# SYSCTL_1.0 register map
Vendor: Texas Instruments
Peripheral module from a debugger description file (folder mspm0l11xx_l13xx).
Registers are 32-bit, read-write, no defined reset value unless marked. A register's access mark holds for its fields unless they carry their own. Offsets are as the file gives them; lines under a group give offsets from that group; [hi:lo] are bit positions; {n}, {i} and the like mark numbered series; 'fields as' and 'values as' point back to an identical list; <NAME> marks a mode.

## SYSCTL
0x1020 SYSCTL_IIDX ro — SYSCTL interrupt index
  [1:0] STAT — The SYSCTL interrupt index (IIDX) register generates a value corresponding to the highest priority pending interrupt source. This value may be used as an address offset for fast, deterministic handling in the interrupt service routine. A read of the IIDX register will clear the corresponding interrupt status in the RIS and MIS registers.
    0=NO_INTR (No interrupt pending); 1=LFOSCGOOD (LFOSCGOOD interrupt pending); 2=ANACLKERR
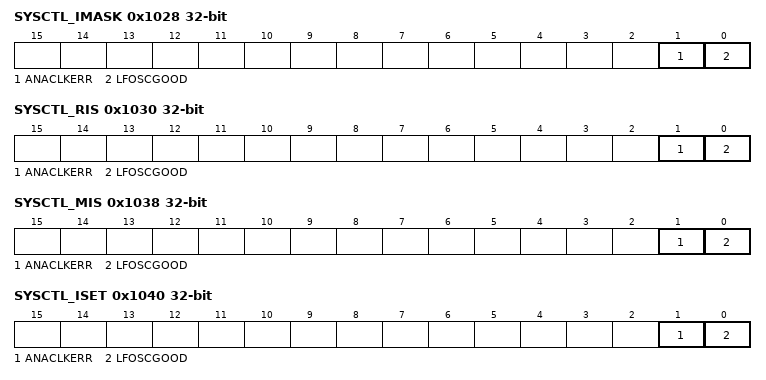
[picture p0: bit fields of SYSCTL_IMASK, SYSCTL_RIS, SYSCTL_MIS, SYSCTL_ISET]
0x1028 SYSCTL_IMASK — SYSCTL interrupt mask
  [1] ANACLKERR — Analog Clocking Consistency Error
    0=DISABLE; 1=ENABLE
  [0] LFOSCGOOD — Enable or disable the LFOSCGOOD interrupt. LFOSCGOOD indicates that the LFOSC has started successfully.
    0=DISABLE (Interrupt disabled); 1=ENABLE (Interrupt enabled)
0x1030 SYSCTL_RIS ro — SYSCTL raw interrupt status
  [1] ANACLKERR — Analog Clocking Consistency Error
    0=FALSE; 1=TRUE
  [0] LFOSCGOOD — Raw status of the LFOSCGOOD interrupt.
    0=FALSE (No interrupt pending); 1=TRUE (Interrupt pending)
0x1038 SYSCTL_MIS ro — SYSCTL masked interrupt status
  [1] ANACLKERR — Analog Clocking Consistency Error
    0=FALSE; 1=TRUE
  [0] LFOSCGOOD — Masked status of the LFOSCGOOD interrupt.
    0=FALSE (No interrupt pending); 1=TRUE (Interrupt pending)
0x1040 SYSCTL_ISET — SYSCTL interrupt set
  [1] ANACLKERR — Analog Clocking Consistency Error
    0=NO_EFFECT; 1=SET
  [0] LFOSCGOOD — Set the LFOSCGOOD interrupt.
    0=NO_EFFECT (Writing 0h hs no effect); 1=SET (Set interrupt)
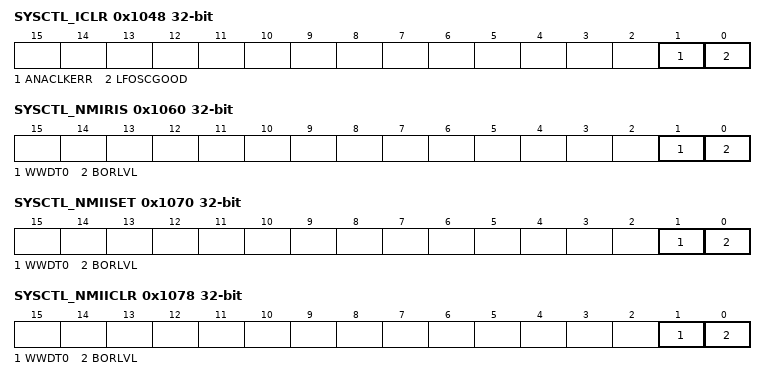
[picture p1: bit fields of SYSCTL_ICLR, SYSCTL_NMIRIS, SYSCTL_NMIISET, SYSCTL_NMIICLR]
0x1048 SYSCTL_ICLR — SYSCTL interrupt clear
  [1] ANACLKERR — Analog Clocking Consistency Error
    0=NO_EFFECT; 1=CLR
  [0] LFOSCGOOD — Clear the LFOSCGOOD interrupt.
    0=NO_EFFECT (Writing 0h has no effect); 1=CLR (Clear interrupt)
0x1050 SYSCTL_NMIIIDX ro — NMI interrupt index
  [1:0] STAT — The NMI interrupt index (NMIIIDX) register generates a value corresponding to the highest priority pending NMI source. This value may be used as an address offset for fast, deterministic handling in the NMI service routine. A read of the NMIIIDX register will clear the corresponding interrupt status in the NMIRIS register.
    0=NO_INTR (No NMI pending); 1=BORLVL (BOR Threshold NMI pending); 2=WWDT0
0x1060 SYSCTL_NMIRIS ro — NMI raw interrupt status
  [1] WWDT0 — Watch Dog 0 Fault
    0=FALSE; 1=TRUE
  [0] BORLVL — Raw status of the BORLVL NMI
    0=FALSE (No interrupt pending); 1=TRUE (Interrupt pending)
0x1070 SYSCTL_NMIISET — NMI interrupt set
  [1] WWDT0 — Watch Dog 0 Fault
    0=NO_EFFECT; 1=SET
  [0] BORLVL — Set the BORLVL NMI
    0=NO_EFFECT (Writing 0h hs no effect); 1=SET (Set interrupt)
0x1078 SYSCTL_NMIICLR — NMI interrupt clear
  [1] WWDT0 — Watch Dog 0 Fault
    0=NO_EFFECT; 1=CLR
  [0] BORLVL — Clr the BORLVL NMI
    0=NO_EFFECT (Writing 0h hs no effect); 1=CLR (Clear interrupt)
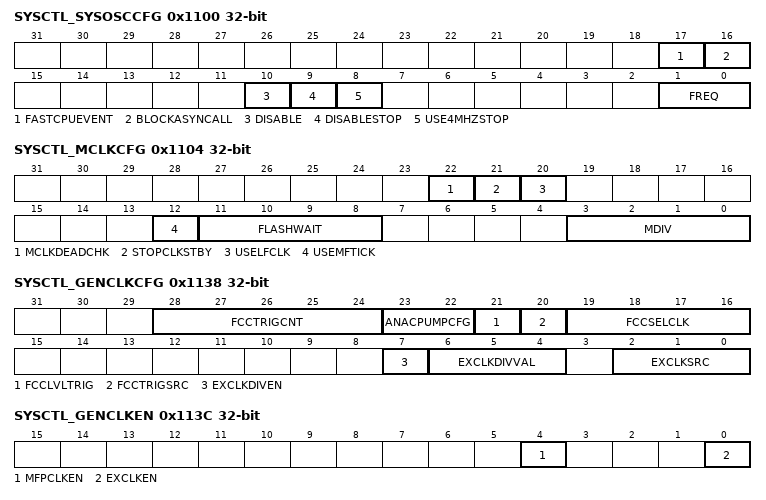
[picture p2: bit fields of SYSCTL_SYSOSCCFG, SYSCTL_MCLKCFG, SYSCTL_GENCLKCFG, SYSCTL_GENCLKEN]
0x1100 SYSCTL_SYSOSCCFG — SYSOSC configuration
  [17] FASTCPUEVENT — FASTCPUEVENT may be used to assert a fast clock request when an interrupt is asserted to the CPU, reducing interrupt latency.
    0=DISABLE (An interrupt to the CPU will not assert a fast clock request); 1=ENABLE (An interrupt to the CPU will assert a fast clock request)
  [16] BLOCKASYNCALL — BLOCKASYNCALL may be used to mask block all asynchronous fast clock requests, preventing hardware from dynamically changing the active clock configuration when operating in a given mode.
    0=DISABLE (Asynchronous fast clock requests are controlled by the requesting peripheral); 1=ENABLE (All asynchronous fast clock requests are blocked)
  [10] DISABLE — DISABLE sets the SYSOSC enable/disable policy. SYSOSC may be powered off in RUN, SLEEP, and STOP modes to reduce power consumption. When SYSOSC is disabled, MCLK and ULPCLK are sourced from LFCLK.
    0=DISABLE (Do not disable SYSOSC); 1=ENABLE (Disable SYSOSC immediately and source MCLK and ULPCLK from LFCLK)
  [9] DISABLESTOP — DISABLESTOP sets the SYSOSC stop mode enable/disable policy. When operating in STOP mode, the SYSOSC may be automatically disabled. When set, ULPCLK will run from LFCLK in STOP mode and SYSOSC will be disabled to reduce power consumption.
    0=DISABLE (Do not disable SYSOSC in STOP mode); 1=ENABLE (Disable SYSOSC in STOP mode and source ULPCLK from LFCLK)
  [8] USE4MHZSTOP — USE4MHZSTOP sets the SYSOSC stop mode frequency policy. When entering STOP mode, the SYSOSC frequency may be automatically switched to 4MHz to reduce SYSOSC power consumption.
    0=DISABLE (Do not gear shift the SYSOSC to 4MHz in STOP mode); 1=ENABLE (Gear shift SYSOSC to 4MHz in STOP mode)
  [1:0] FREQ — Target operating frequency for the system oscillator (SYSOSC)
    0=SYSOSCBASE (Base frequency (32MHz)); 1=SYSOSC4M (Low frequency (4MHz)); 2=SYSOSCUSER (User-trimmed frequency (16 or 24 MHz)); 3=SYSOSCTURBO (Turbo frequency (48MHz))
0x1104 SYSCTL_MCLKCFG — Main clock (MCLK) configuration
  [22] MCLKDEADCHK — MCLKDEADCHK enables or disables the continuous MCLK dead check monitor. LFCLK must be running before MCLKDEADCHK is enabled.
    0=DISABLE (The MCLK dead check monitor is disabled); 1=ENABLE (The MCLK dead check monitor is enabled)
  [21] STOPCLKSTBY — STOPCLKSTBY sets the STANDBY mode policy (STANDBY0 or STANDBY1). When set, ULPCLK and LFCLK are disabled to all peripherals in STANDBY mode, with the exception of TIMG0 and TIMG1 which continue to run. Wake-up is only possible via an asynchronous fast clock request.
    0=DISABLE (ULPCLK/LFCLK runs to all PD0 peripherals in STANDBY mode); 1=ENABLE (ULPCLK/LFCLK is disabled to all peripherals in STANDBY mode except TIMG0 and TIMG1)
  [20] USELFCLK — USELFCLK sets the MCLK source policy. Set USELFCLK to use LFCLK as the MCLK source. Note that setting USELFCLK does not disable SYSOSC, and SYSOSC remains available for direct use by analog modules.
    0=DISABLE (MCLK will not use the low frequency clock (LFCLK)); 1=ENABLE (MCLK will use the low frequency clock (LFCLK))
  [12] USEMFTICK — USEMFTICK specifies whether the 4MHz constant-rate clock (MFCLK) to peripherals is enabled or disabled. When enabled, MDIV must be disabled (set to 0h=/1).
    0=DISABLE (The 4MHz rate MFCLK to peripherals is enabled); 1=ENABLE (The 4MHz rate MFCLK to peripherals is enabled.)
  [11:8] FLASHWAIT — FLASHWAIT specifies the number of flash wait states when MCLK is sourced from HSCLK. FLASHWAIT has no effect when MCLK is sourced from SYSOSC or LFCLK.
    0=WAIT0 (No flash wait states are applied); 1=WAIT1 (One flash wait state is applied); 2=WAIT2 (2 flash wait states are applied)
  [3:0] MDIV — MDIV may be used to divide the MCLK frequency when MCLK is sourced from SYSOSC. MDIV=0h corresponds to /1 (no divider). MDIV=1h corresponds to /2 (divide-by-2). MDIV=Fh corresponds to /16 (divide-by-16). MDIV may be set between /1 and /16 on an integer basis.
0x1138 SYSCTL_GENCLKCFG — General clock configuration
  [28:24] FCCTRIGCNT — FCCTRIGCNT specifies the number of trigger clock periods in the trigger window. FCCTRIGCNT=0h (one trigger clock period) up to 1Fh (32 trigger clock periods) may be specified.
  [23:22] ANACPUMPCFG — ANACPUMPCFG selects the analog mux charge pump (VBOOST) enable method.
    0=ONDEMAND (VBOOST is enabled on request from a COMP, GPAMP, or OPA); 1=ONACTIVE (VBOOST is enabled when the device is in RUN or SLEEP mode, or when a COMP/GPAMP/OPA is enabled); 2=ONALWAYS (VBOOST is always enabled)
  [21] FCCLVLTRIG — FCCLVLTRIG selects the frequency clock counter (FCC) trigger mode.
    0=RISE2RISE (Rising edge to rising edge triggered); 1=LEVEL (Level triggered)
  [20] FCCTRIGSRC — FCCTRIGSRC selects the frequency clock counter (FCC) trigger source.
    0=EXTPIN (FCC trigger is the external pin); 1=LFCLK (FCC trigger is the LFCLK)
  [19:16] FCCSELCLK — FCCSELCLK selectes the frequency clock counter (FCC) clock source.
    0=MCLK (FCC clock is MCLK); 1=SYSOSC (FCC clock is SYSOSC); 3=EXTCLK (FCC clock is the CLK_OUT selection); 7=FCCIN (FCC clock is the FCCIN external input)
  [7] EXCLKDIVEN — EXCLKDIVEN enables or disables the divider function of the CLK_OUT external clock output block.
    0=PASSTHRU (CLock divider is disabled (passthrough, EXCLKDIVVAL is not applied)); 1=ENABLE (Clock divider is enabled (EXCLKDIVVAL is applied))
  [6:4] EXCLKDIVVAL — EXCLKDIVVAL selects the divider value for the divider in the CLK_OUT external clock output block.
    0=DIV2 (CLK_OUT source is divided by 2); 1=DIV4 (CLK_OUT source is divided by 4); 2=DIV6 (CLK_OUT source is divided by 6); 3=DIV8 (CLK_OUT source is divided by 8); 4=DIV10 (CLK_OUT source is divided by 10); 5=DIV12 (CLK_OUT source is divided by 12); 6=DIV14 (CLK_OUT source is divided by 14); 7=DIV16 (CLK_OUT source is divided by 16)
  [2:0] EXCLKSRC — EXCLKSRC selects the source for the CLK_OUT external clock output block. ULPCLK and MFPCLK require the CLK_OUT divider (EXCLKDIVEN) to be enabled
    0=SYSOSC (CLK_OUT is SYSOSC); 1=ULPCLK (CLK_OUT is ULPCLK (EXCLKDIVEN must be enabled)); 2=LFCLK (CLK_OUT is LFCLK); 3=MFPCLK (CLK_OUT is MFPCLK (EXCLKDIVEN must be enabled))
0x113C SYSCTL_GENCLKEN — General clock enable control
  [4] MFPCLKEN — MFPCLKEN enables the middle frequency precision clock (MFPCLK).
    0=DISABLE (MFPCLK is disabled); 1=ENABLE (MFPCLK is enabled)
  [0] EXCLKEN — EXCLKEN enables the CLK_OUT external clock output block.
    0=DISABLE (CLK_OUT block is disabled); 1=ENABLE (CLK_OUT block is enabled)
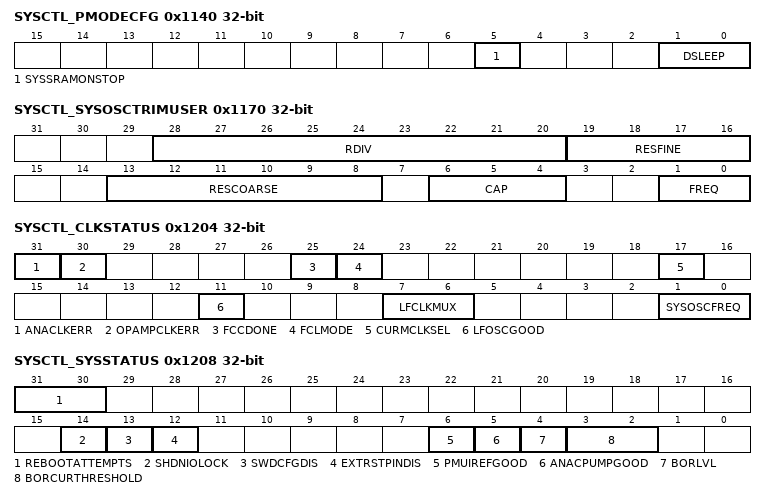
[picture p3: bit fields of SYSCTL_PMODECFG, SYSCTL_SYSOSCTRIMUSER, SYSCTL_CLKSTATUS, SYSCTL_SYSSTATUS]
0x1140 SYSCTL_PMODECFG — Power mode configuration
  [5] SYSSRAMONSTOP — SYSSRAMONSTOP selects whether the SRAM controller is enabled or disabled in STOP mode.
    0=DISABLE (SRAM controller is disabled in STOP mode (lower power consumption)); 1=ENABLE (SRAM controller is left enabled in STOP mode (faster wake-up))
  [1:0] DSLEEP — DSLEEP selects the operating mode to enter upon a DEEPSLEEP request from the CPU.
    0=STOP (STOP mode is entered); 1=STANDBY (STANDBY mode is entered); 2=SHUTDOWN (SHUTDOWN mode is entered)
0x1150 SYSCTL_FCC ro — Frequency clock counter (FCC) count
  [21:0] DATA — Frequency clock counter (FCC) count value.
0x1170 SYSCTL_SYSOSCTRIMUSER — SYSOSC user-specified trim
  [28:20] RDIV — RDIV specifies the frequency correction loop (FCL) resistor trim. This value changes with the target frequency.
  [19:16] RESFINE — RESFINE specifies the resister fine trim. This value changes with the target frequency.
  [13:8] RESCOARSE — RESCOARSE specifies the resister coarse trim. This value changes with the target frequency.
  [6:4] CAP — CAP specifies the SYSOSC capacitor trim. This value changes with the target frequency.
  [1:0] FREQ — FREQ specifies the target user-trimmed frequency for SYSOSC.
    1=SYSOSC16M (16MHz user frequency); 2=SYSOSC24M (24MHz user frequency)
0x1178 SYSCTL_SRAMBOUNDARY — SRAM Write Boundary
  [19:5] ADDR — SRAM boundary configuration. The value configured into this acts such that: SRAM accesses to addresses less than or equal value will be RW only. SRAM accesses to addresses greater than value will be RX only. Value of 0 is not valid (system will have no stack). If set to 0, the system acts as if the entire SRAM is RWX. Any non-zero value can be configured, including a value = SRAM size.
0x1180 SYSCTL_SYSTEMCFG — System configuration
  [0] WWDTLP0RSTDIS — WWDTLP0RSTDIS specifies whether a WWDT Error Event will trigger a BOOTRST or an NMI.
    0=FALSE (WWDTLP0 Error Event will trigger a BOOTRST); 1=TRUE (WWDTLP0 Error Event will trigger an NMI)
0x1200 SYSCTL_WRITELOCK — SYSCTL register write lockout
  [0] ACTIVE — ACTIVE controls whether critical SYSCTL registers are write protected or not.
    0=DISABLE (Allow writes to lockable registers); 1=ENABLE (Disallow writes to lockable registers)
0x1204 SYSCTL_CLKSTATUS ro — Clock module (CKM) status
  [31] ANACLKERR — ANACLKERR is set when the device clock configuration does not support an enabled analog peripheral mode and the analog peripheral may not be functioning as expected.
    0=FALSE (No analog clock errors detected); 1=TRUE (Analog clock error detected)
  [30] OPAMPCLKERR — OPAMPCLKERR is set when the device clock configuration does not support an enabled OPA mode and the OPA may not be functioning as expected.
    0=FALSE (No OPA clock generation errors detected); 1=TRUE (OPA clock generation error detected)
  [25] FCCDONE — FCCDONE indicates when a frequency clock counter capture is complete.
    0=NOTDONE (FCC capture is not done); 1=DONE (FCC capture is done)
  [24] FCLMODE — FCLMODE indicates if the SYSOSC frequency correction loop (FCL) is enabled.
    0=DISABLED (SYSOSC FCL is disabled); 1=ENABLED (SYSOSC FCL is enabled)
  [17] CURMCLKSEL — CURMCLKSEL indicates if MCLK is currently sourced from LFCLK.
    0=NOTLFCLK (MCLK is not sourced from LFCLK); 1=LFCLK (MCLK is sourced from LFCLK)
  [11] LFOSCGOOD — LFOSCGOOD indicates when the LFOSC startup has completed and the LFOSC is ready for use.
    0=FALSE (LFOSC is not ready); 1=TRUE (LFOSC is ready)
  [7:6] LFCLKMUX — LFCLKMUX indicates if LFCLK is sourced from the internal LFOSC, the low frequency crystal (LFXT), or the LFCLK_IN digital clock input.
    0=LFOSC (LFCLK is sourced from the internal LFOSC); 1=LFXT (LFCLK is sourced from the LFXT (crystal)); 2=EXLF (LFCLK is sourced from LFCLK_IN (external digital clock input))
  [1:0] SYSOSCFREQ — SYSOSCFREQ indicates the current SYSOSC operating frequency.
    0=SYSOSC32M (SYSOSC is at base frequency (32MHz)); 1=SYSOSC4M (SYSOSC is at low frequency (4MHz)); 2=SYSOSCUSER (SYSOSC is at the user-trimmed frequency (16 or 24MHz)); 3=SYSOSCTURBO (Reserved)
0x1208 SYSCTL_SYSSTATUS ro — System status information
  [31:30] REBOOTATTEMPTS — REBOOTATTEMPTS indicates the number of boot attempts taken before the user application starts.
  [14] SHDNIOLOCK — SHDNIOLOCK indicates when IO is locked due to SHUTDOWN
    0=FALSE (IO IS NOT Locked due to SHUTDOWN); 1=TRUE (IO IS Locked due to SHUTDOWN)
  [13] SWDCFGDIS — SWDCFGDIS indicates when user has disabled the use of SWD Port
    0=FALSE (SWD Port Enabled); 1=TRUE (SWD Port Disabled)
  [12] EXTRSTPINDIS — EXTRSTPINDIS indicates when user has disabled the use of external reset pin
    0=FALSE (External Reset Pin Enabled); 1=TRUE (External Reset Pin Disabled)
  [6] PMUIREFGOOD — PMUIREFGOOD is set by hardware when the PMU current reference is ready.
    0=FALSE (IREF is not ready); 1=TRUE (IREF is ready)
  [5] ANACPUMPGOOD — ANACPUMPGOOD is set by hardware when the VBOOST analog mux charge pump is ready.
    0=FALSE (VBOOST is not ready); 1=TRUE (VBOOST is ready)
  [4] BORLVL — BORLVL indicates if a BOR event occured and the BOR threshold was switched to BOR0 by hardware.
    0=FALSE (No BOR violation occured); 1=TRUE (A BOR violation occured and the BOR threshold was switched to BOR0)
  [3:2] BORCURTHRESHOLD — BORCURTHRESHOLD indicates the active brown-out reset supply monitor configuration.
    0=BORMIN (Default minimum threshold; a BOR0- violation triggers a BOR); 1=BORLEVEL1 (A BOR1- violation generates a BORLVL interrupt); 2=BORLEVEL2 (A BOR2- violation generates a BORLVL interrupt); 3=BORLEVEL3 (A BOR3- violation generates a BORLVL interrupt)
0x1220 SYSCTL_RSTCAUSE ro — Reset cause
  [4:0] ID — ID is a read-to-clear field which indicates the lowest level reset cause since the last read.
    0=NORST (No reset since last read); 1=PORHWFAIL (POR- violation, SHUTDNSTOREx or PMU trim parity fault); 2=POREXNRST (NRST triggered POR (>1s hold)); 3=PORSW (Software triggered POR); 4=BORSUPPLY (BOR0- violation); 5=BORWAKESHUTDN (SHUTDOWN mode exit); 8=BOOTNONPMUPARITY (Non-PMU trim parity fault); 9=BOOTCLKFAIL (Fatal clock failure); 10=BOOTSW (Software triggered BOOTRST); 12=BOOTEXNRST (NRST triggered BOOTRST (<1s hold)); 16=SYSBSLEXIT (BSL exit); 17=SYSBSLENTRY (BSL entry); 18=SYSWWDT0 (WWDT0 violation); 19=SYSWWDT1 (WWDT1 violation); 20=SYSFLASHECC (Flash uncorrectable ECC error); 21=SYSCPULOCK (CPULOCK violation); 26=SYSDBG (Debug triggered SYSRST); 27=SYSSW (Software triggered SYSRST); 28=CPUDBG (Debug triggered CPURST); 29=CPUSW (Software triggered CPURST)
0x1300 SYSCTL_RESETLEVEL — Reset level for application-triggered reset command
  [2:0] LEVEL — LEVEL is used to specify the type of reset to be issued when RESETCMD is set to generate a software triggered reset.
    0=CPU (Issue a SYSRST (CPU plus peripherals only)); 1=BOOT (Issue a BOOTRST (CPU, peripherals, and boot configuration routine)); 2=BOOTLOADERENTRY (Issue a SYSRST and enter the boot strap loader (BSL)); 3=POR (Issue a power-on reset (POR)); 4=BOOTLOADEREXIT (Issue a SYSRST and exit the boot strap loader (BSL))
0x1304 SYSCTL_RESETCMD — Execute an application-triggered reset command
  [0] GO — Execute the reset specified in RESETLEVEL.LEVEL. Must be written together with the KEY.
    1=TRUE (Issue reset)
0x1308 SYSCTL_BORTHRESHOLD — BOR threshold selection
  [1:0] LEVEL — LEVEL specifies the desired BOR threshold and BOR mode.
    values as SYSCTL_SYSSTATUS.BORCURTHRESHOLD
0x130C SYSCTL_BORCLRCMD — Set the BOR threshold
  [0] GO — GO clears any prior BOR violation status indications and attempts to change the active BOR mode to that specified in the LEVEL field of the BORTHRESHOLD register.
    1=TRUE (Issue clear)
0x1310 SYSCTL_SYSOSCFCLCTL — SYSOSC frequency correction loop (FCL) ROSC enable
  [0] SETUSEFCL — Set SETUSEFCL to enable the frequency correction loop in SYSOSC. An appropriate resistor must be populated on the ROSC pin. Once enabled, this state is locked until the next BOOTRST.
    1=TRUE (Enable the SYSOSC FCL)
0x131C SYSCTL_SHDNIOREL — SHUTDOWN IO release control
  [0] RELEASE — Set RELEASE to release the IO after a SHUTDOWN mode exit.
    1=TRUE (Release IO)
0x1320 SYSCTL_EXRSTPIN — Disable the reset function of the NRST pin
  [0] DISABLE — Set DISABLE to disable the reset function of the NRST pin. Once set, this configuration is locked until the next POR.
    0=FALSE (Reset function of NRST pin is enabled); 1=TRUE (Reset function of NRST pin is disabled)
0x1324 SYSCTL_SYSSTATUSCLR — Clear sticky bits of SYSSTATUS
  [0] ALLECC — Set ALLECC to clear all ECC related SYSSTATUS indicators.
    1=CLEAR (Clear ECC error state)
0x1328 SYSCTL_SWDCFG — Disable the SWD function on the SWD pins
  [0] DISABLE — Set DISABLE to disable the SWD function on SWD pins, allowing the SWD pins to be used as GPIO.
    1=TRUE (Disable SWD function on SWD pins)
0x132C SYSCTL_FCCCMD — Frequency clock counter start capture
  [0] GO — Set GO to start a capture with the frequency clock counter (FCC).
    1=TRUE
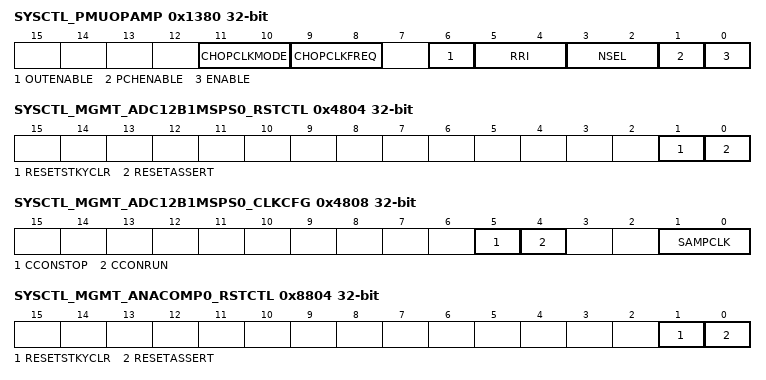
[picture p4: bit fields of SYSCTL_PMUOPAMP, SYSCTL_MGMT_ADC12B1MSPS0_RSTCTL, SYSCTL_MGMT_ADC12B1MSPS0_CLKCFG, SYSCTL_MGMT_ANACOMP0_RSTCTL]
0x1380 SYSCTL_PMUOPAMP — GPAMP control
  [11:10] CHOPCLKMODE — CHOPCLKMODE selects the GPAMP chopping mode.
    0=CHOPDISABLED (Chopping disabled); 1=REGCHOP (Normal chopping); 2=ADCASSIST (ADC Assisted chopping)
  [9:8] CHOPCLKFREQ — CHOPCLKFREQ selects the GPAMP chopping clock frequency
    0=CLK16KHZ (16kHz); 1=CLK8KHZ (8kHz); 2=CLK4KHZ (4kHz); 3=CLK2KHZ (2kHz)
  [6] OUTENABLE — Set OUTENABLE to connect the GPAMP output signal to the GPAMP_OUT pin
    0=FALSE (GPAMP_OUT signal is not connected to the GPAMP_OUT pin); 1=TRUE (GPAMP_OUT signal is connected to the GPAMP_OUT pin)
  [5:4] RRI — RRI selects the rail-to-rail input mode.
    0=MODE0 (PMOS input pairs); 1=MODE1 (NMOS input pairs); 2=MODE2 (Rail-to-rail mode); 3=MODE3 (Sample channel 0)
  [3:2] NSEL — NSEL selects the GPAMP negative channel input.
    0=SEL0 (GPAMP_OUT pin connected to negative channel); 1=SEL1 (GPAMP_IN- pin connected to negative channel); 2=SEL2 (GPAMP_OUT signal connected to negative channel); 3=SEL3 (No channel selected)
  [1] PCHENABLE — Set PCHENABLE to enable the positive channel input.
    0=FALSE (Positive channel disabled); 1=TRUE (GPAMP_IN+ connected to positive channel)
  [0] ENABLE — Set ENABLE to turn on the GPAMP.
    0=FALSE (GPAMP is disabled); 1=TRUE (GPAMP is enabled)
{0x1400+4i} SYSCTL_SHUTDNSTORE{i} (i=0..3) — Shutdown storage memory (byte {i})
  [7:0] DATA — Shutdown storage byte {i}
0x4800 SYSCTL_MGMT_ADC12B1MSPS0_PWREN — IP Enable Register
  [0] ENABLE — IP Enable
    0=Disable; 1=Enable
0x4804 SYSCTL_MGMT_ADC12B1MSPS0_RSTCTL — Power Control Register - Write Only Register, Always Read as 0
  [1] RESETSTKYCLR — Clear the RESET STICKY Bit
    1=Clear
  [0] RESETASSERT — Assert Reset to IP Domain.
    1=Do
0x4808 SYSCTL_MGMT_ADC12B1MSPS0_CLKCFG — IP Clock Configuration Register
  [5] CCONSTOP — Conversion Clock is ON during STOP Mode
    0=Disable; 1=Enable
  [4] CCONRUN — Conversion Clock is ON during RUN Mode
    0=Disable; 1=Enable
  [1:0] SAMPCLK — Sample Window Clock
    0=ULPCLK; 1=SYSOSC; 2=HFCLK
0x4814 SYSCTL_MGMT_ADC12B1MSPS0_STAT ro — IP State Register - Read Only
  [16] RESETSTKY — IP has been Reset
    0=clear; 1=Set
0x8800 SYSCTL_MGMT_ANACOMP0_PWREN — IP Enable Register
  [0] ENABLE — IP Enable
    0=Disable; 1=Enable
0x8804 SYSCTL_MGMT_ANACOMP0_RSTCTL — Power Control Register - Write Only Register, Always Read as 0
  fields as SYSCTL_MGMT_ADC12B1MSPS0_RSTCTL
0x8808 SYSCTL_MGMT_ANACOMP0_CLKCFG — IP Clock Configuration Register
  [8] BLOCKASYNC — Async Clock Request is blocked from starting SYSOSC or forcing bus clock to 32MHz
    0=Disable; 1=Enable
0x8814 SYSCTL_MGMT_ANACOMP0_STAT ro — IP State Register - Read Only
  [16] RESETSTKY — IP has been Reset
    0=clear; 1=Set
0x20800 SYSCTL_MGMT_OPAMP0_PWREN — IP Enable Register
  [0] ENABLE — IP Enable
    0=Disable; 1=Enable
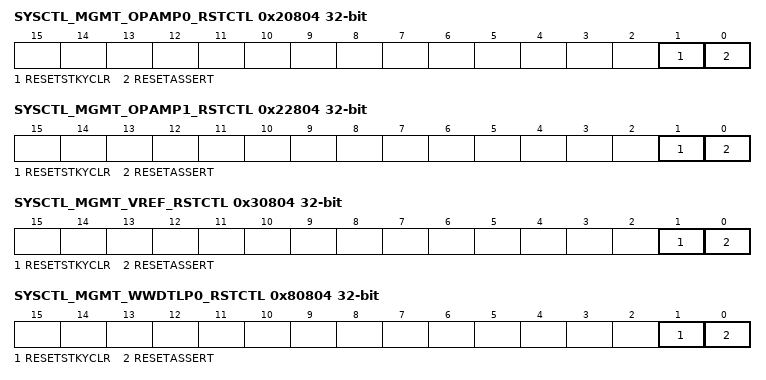
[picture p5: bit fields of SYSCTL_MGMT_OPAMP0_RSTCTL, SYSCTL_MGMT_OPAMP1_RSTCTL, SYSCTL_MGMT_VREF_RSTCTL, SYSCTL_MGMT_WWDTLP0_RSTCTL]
0x20804 SYSCTL_MGMT_OPAMP0_RSTCTL — Power Control Register - Write Only Register, Always Read as 0
  fields as SYSCTL_MGMT_ADC12B1MSPS0_RSTCTL
0x20814 SYSCTL_MGMT_OPAMP0_STAT ro — IP State Register - Read Only
  [16] RESETSTKY — IP has been Reset
    0=clear; 1=Set
0x22800 SYSCTL_MGMT_OPAMP1_PWREN — IP Enable Register
  [0] ENABLE — IP Enable
    0=Disable; 1=Enable
0x22804 SYSCTL_MGMT_OPAMP1_RSTCTL — Power Control Register - Write Only Register, Always Read as 0
  fields as SYSCTL_MGMT_ADC12B1MSPS0_RSTCTL
0x22814 SYSCTL_MGMT_OPAMP1_STAT ro — IP State Register - Read Only
  [16] RESETSTKY — IP has been Reset
    0=clear; 1=Set
0x30800 SYSCTL_MGMT_VREF_PWREN — IP Enable Register
  [0] ENABLE — IP Enable
    0=Disable; 1=Enable
0x30804 SYSCTL_MGMT_VREF_RSTCTL — Power Control Register - Write Only Register, Always Read as 0
  fields as SYSCTL_MGMT_ADC12B1MSPS0_RSTCTL
0x30814 SYSCTL_MGMT_VREF_STAT ro — IP State Register - Read Only
  [16] RESETSTKY — IP has been Reset
    0=clear; 1=Set
0x80800 SYSCTL_MGMT_WWDTLP0_PWREN — IP Enable Register
  [0] ENABLE — IP Enable
    0=Disable; 1=Enable
0x80804 SYSCTL_MGMT_WWDTLP0_RSTCTL — Power Control Register - Write Only Register, Always Read as 0
  fields as SYSCTL_MGMT_ADC12B1MSPS0_RSTCTL
0x80814 SYSCTL_MGMT_WWDTLP0_STAT ro — IP State Register - Read Only
  [16] RESETSTKY — IP has been Reset
    0=clear; 1=Set
{0x84800+0x2000*i} SYSCTL_MGMT_GPTIMER16B2CCLP{i}_PWREN (i=0..2) — IP Enable Register
  [0] ENABLE — IP Enable
    0=Disable; 1=Enable
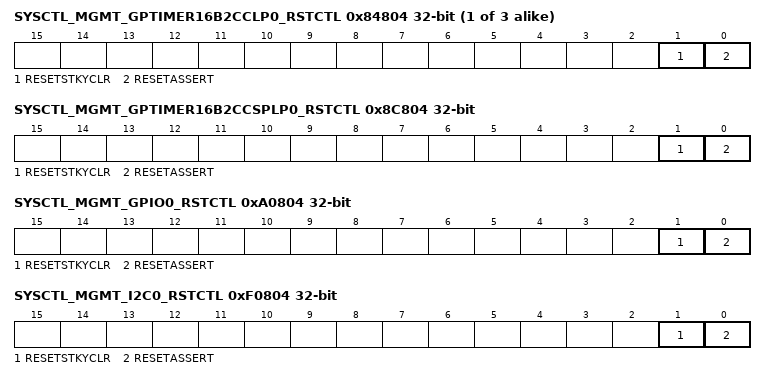
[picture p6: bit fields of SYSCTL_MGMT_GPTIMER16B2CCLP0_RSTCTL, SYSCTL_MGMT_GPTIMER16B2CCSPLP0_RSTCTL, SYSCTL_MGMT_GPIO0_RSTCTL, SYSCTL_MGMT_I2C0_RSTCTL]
{0x84804+0x2000*i} SYSCTL_MGMT_GPTIMER16B2CCLP{i}_RSTCTL (i=0..2) — Power Control Register - Write Only Register, Always Read as 0
  fields as SYSCTL_MGMT_ADC12B1MSPS0_RSTCTL
{0x84814+0x2000*i} SYSCTL_MGMT_GPTIMER16B2CCLP{i}_STAT ro (i=0..2) — IP State Register - Read Only
  [16] RESETSTKY — IP has been Reset
    0=clear; 1=Set
0x8C800 SYSCTL_MGMT_GPTIMER16B2CCSPLP0_PWREN — IP Enable Register
  [0] ENABLE — IP Enable
    0=Disable; 1=Enable
0x8C804 SYSCTL_MGMT_GPTIMER16B2CCSPLP0_RSTCTL — Power Control Register - Write Only Register, Always Read as 0
  fields as SYSCTL_MGMT_ADC12B1MSPS0_RSTCTL
0x8C814 SYSCTL_MGMT_GPTIMER16B2CCSPLP0_STAT ro — IP State Register - Read Only
  [16] RESETSTKY — IP has been Reset
    0=clear; 1=Set
0xA0800 SYSCTL_MGMT_GPIO0_PWREN — IP Enable Register
  [0] ENABLE — IP Enable
    0=Disable; 1=Enable
0xA0804 SYSCTL_MGMT_GPIO0_RSTCTL — Power Control Register - Write Only Register, Always Read as 0
  fields as SYSCTL_MGMT_ADC12B1MSPS0_RSTCTL
0xA0814 SYSCTL_MGMT_GPIO0_STAT ro — IP State Register - Read Only
  [16] RESETSTKY — IP has been Reset
    0=clear; 1=Set
0xF0800 SYSCTL_MGMT_I2C0_PWREN — IP Enable Register
  [0] ENABLE — IP Enable
    0=Disable; 1=Enable
0xF0804 SYSCTL_MGMT_I2C0_RSTCTL — Power Control Register - Write Only Register, Always Read as 0
  fields as SYSCTL_MGMT_ADC12B1MSPS0_RSTCTL
0xF0808 SYSCTL_MGMT_I2C0_CLKCFG — IP Clock Configuration Register
  fields as SYSCTL_MGMT_ANACOMP0_CLKCFG
0xF0814 SYSCTL_MGMT_I2C0_STAT ro — IP State Register - Read Only
  [16] RESETSTKY — IP has been Reset
    0=clear; 1=Set
0xF2800 SYSCTL_MGMT_I2C1_PWREN — IP Enable Register
  [0] ENABLE — IP Enable
    0=Disable; 1=Enable
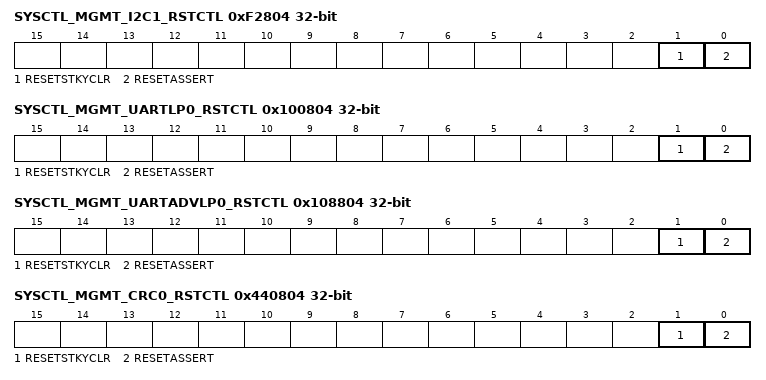
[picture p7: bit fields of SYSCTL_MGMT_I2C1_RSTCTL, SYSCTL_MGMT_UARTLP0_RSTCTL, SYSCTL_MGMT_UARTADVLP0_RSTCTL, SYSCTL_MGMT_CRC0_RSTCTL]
0xF2804 SYSCTL_MGMT_I2C1_RSTCTL — Power Control Register - Write Only Register, Always Read as 0
  fields as SYSCTL_MGMT_ADC12B1MSPS0_RSTCTL
0xF2808 SYSCTL_MGMT_I2C1_CLKCFG — IP Clock Configuration Register
  fields as SYSCTL_MGMT_ANACOMP0_CLKCFG
0xF2814 SYSCTL_MGMT_I2C1_STAT ro — IP State Register - Read Only
  [16] RESETSTKY — IP has been Reset
    0=clear; 1=Set
0x100800 SYSCTL_MGMT_UARTLP0_PWREN — IP Enable Register
  [0] ENABLE — IP Enable
    0=Disable; 1=Enable
0x100804 SYSCTL_MGMT_UARTLP0_RSTCTL — Power Control Register - Write Only Register, Always Read as 0
  fields as SYSCTL_MGMT_ADC12B1MSPS0_RSTCTL
0x100808 SYSCTL_MGMT_UARTLP0_CLKCFG — IP Clock Configuration Register
  fields as SYSCTL_MGMT_ANACOMP0_CLKCFG
0x100814 SYSCTL_MGMT_UARTLP0_STAT ro — IP State Register - Read Only
  [16] RESETSTKY — IP has been Reset
    0=clear; 1=Set
0x108800 SYSCTL_MGMT_UARTADVLP0_PWREN — IP Enable Register
  [0] ENABLE — IP Enable
    0=Disable; 1=Enable
0x108804 SYSCTL_MGMT_UARTADVLP0_RSTCTL — Power Control Register - Write Only Register, Always Read as 0
  fields as SYSCTL_MGMT_ADC12B1MSPS0_RSTCTL
0x108808 SYSCTL_MGMT_UARTADVLP0_CLKCFG — IP Clock Configuration Register
  fields as SYSCTL_MGMT_ANACOMP0_CLKCFG
0x108814 SYSCTL_MGMT_UARTADVLP0_STAT ro — IP State Register - Read Only
  [16] RESETSTKY — IP has been Reset
    0=clear; 1=Set
0x440800 SYSCTL_MGMT_CRC0_PWREN — IP Enable Register
  [0] ENABLE — IP Enable
    0=Disable; 1=Enable
0x440804 SYSCTL_MGMT_CRC0_RSTCTL — Power Control Register - Write Only Register, Always Read as 0
  fields as SYSCTL_MGMT_ADC12B1MSPS0_RSTCTL
0x440814 SYSCTL_MGMT_CRC0_STAT ro — IP State Register - Read Only
  [16] RESETSTKY — IP has been Reset
    0=clear; 1=Set
0x468800 SYSCTL_MGMT_SPI0_PWREN — IP Enable Register
  [0] ENABLE — IP Enable
    0=Disable; 1=Enable
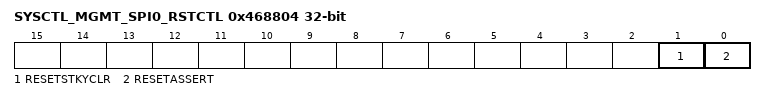
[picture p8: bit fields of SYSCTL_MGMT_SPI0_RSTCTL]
0x468804 SYSCTL_MGMT_SPI0_RSTCTL — Power Control Register - Write Only Register, Always Read as 0
  fields as SYSCTL_MGMT_ADC12B1MSPS0_RSTCTL
0x468808 SYSCTL_MGMT_SPI0_CLKCFG — IP Clock Configuration Register
  fields as SYSCTL_MGMT_ANACOMP0_CLKCFG
0x468814 SYSCTL_MGMT_SPI0_STAT ro — IP State Register - Read Only
  [16] RESETSTKY — IP has been Reset
    0=clear; 1=Set
